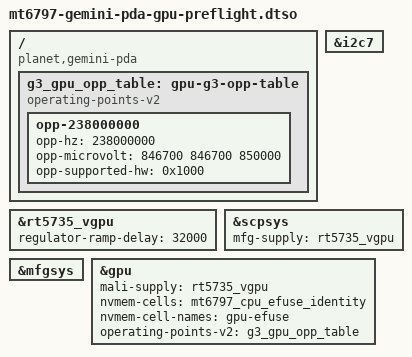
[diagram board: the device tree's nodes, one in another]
// SPDX-License-Identifier: GPL-2.0-only
/*
 * Planet Computers Gemini PDA active GPU no-job preflight overlay.
 *
 * Apply this overlay only to a recoverable RAM boot and run
 * tools/gemini/capture-gpu-preflight.sh from a dedicated initramfs which never
 * opens a DRM node.  Panfrost probe actively changes the GPU rail, clocks,
 * reset and power domains even when no userspace job is submitted.  The base
 * DT keeps every node below disabled, so omitting the overlay is the complete
 * rollback.
 */

/dts-v1/;
/plugin/;

/ {
	compatible = "planet,gemini-pda", "mediatek,mt6797";

	/*
	 * G3 admits one selector step above the inherited 843750 uV state and
	 * one clock rate only.  A later gate must qualify every other OPP.
	 */
	g3_gpu_opp_table: gpu-g3-opp-table {
		compatible = "operating-points-v2";

		opp-238000000 {
			opp-hz = /bits/ 64 <238000000>;
			opp-microvolt = <846700 846700 850000>;
			opp-supported-hw = <0x1000>;
		};
	};
};

&i2c7 {
	status = "okay";
};

&rt5735_vgpu {
	regulator-ramp-delay = <32000>;
	status = "okay";
};

/*
 * Panfrost attaches the four MFG core domains before its OPP setup takes a
 * regulator vote.  Make the parent MFG transition own the VGPU prerequisite
 * so the rail is enabled before PWR_ON is asserted and remains ordered for
 * every later runtime transition.
 */
&scpsys {
	mfg-supply = <&rt5735_vgpu>;
};

&mfgsys {
	status = "okay";
};

&gpu {
	mali-supply = <&rt5735_vgpu>;
	nvmem-cells = <&mt6797_cpu_efuse_identity>;
	nvmem-cell-names = "gpu-efuse";
	operating-points-v2 = <&g3_gpu_opp_table>;
	status = "okay";
};
